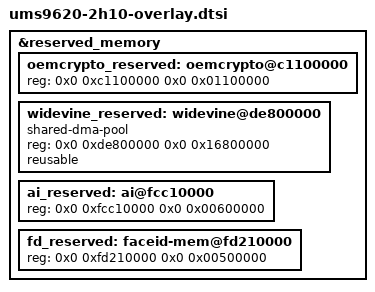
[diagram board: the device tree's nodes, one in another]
&reserved_memory {
	/* Encrypt and decrypt widevine video */
	oemcrypto_reserved: oemcrypto@c1100000 {
		reg = <0x0 0xc1100000 0x0 0x01100000>;
	};

	widevine_reserved: widevine@de800000 {
		compatible = "shared-dma-pool";
		reg = <0x0 0xde800000 0x0 0x16800000>;
		reusable;
	};

	ai_reserved: ai@fcc10000 {
		reg = <0x0 0xfcc10000 0x0 0x00600000>;
	};

	fd_reserved: faceid-mem@fd210000 {
		reg = <0x0 0xfd210000 0x0 0x00500000>;
	};
};

